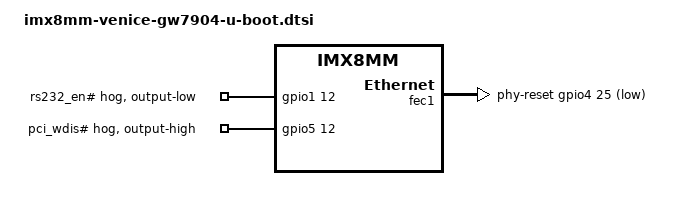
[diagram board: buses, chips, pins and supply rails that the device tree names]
// SPDX-License-Identifier: GPL-2.0+
/*
 * Copyright 2022 Gateworks Corporation
 */

#include "imx8mm-venice-u-boot.dtsi"

&gpio1 {
	rs232en {
		gpio-hog;
		output-low;
		gpios = <12 GPIO_ACTIVE_HIGH>;
		line-name = "rs232_en#";
	};
};

&gpio5 {
	pci_wdis {
		gpio-hog;
		output-high;
		gpios = <12 GPIO_ACTIVE_HIGH>;
		line-name = "pci_wdis#";
	};
};

&fec1 {
	phy-reset-gpios = <&gpio4 25 GPIO_ACTIVE_LOW>;
	phy-reset-duration = <1>;
	phy-reset-post-delay = <300>;
};

&pinctrl_fec1 {
	bootph-pre-ram;
};

&{/soc@0/bus@30800000/i2c@30a30000/pmic@4b} {
	bootph-pre-ram;
};

&{/soc@0/bus@30800000/i2c@30a30000/pmic@4b/regulators} {
	bootph-pre-ram;
};

&pinctrl_pmic {
	bootph-pre-ram;
};
